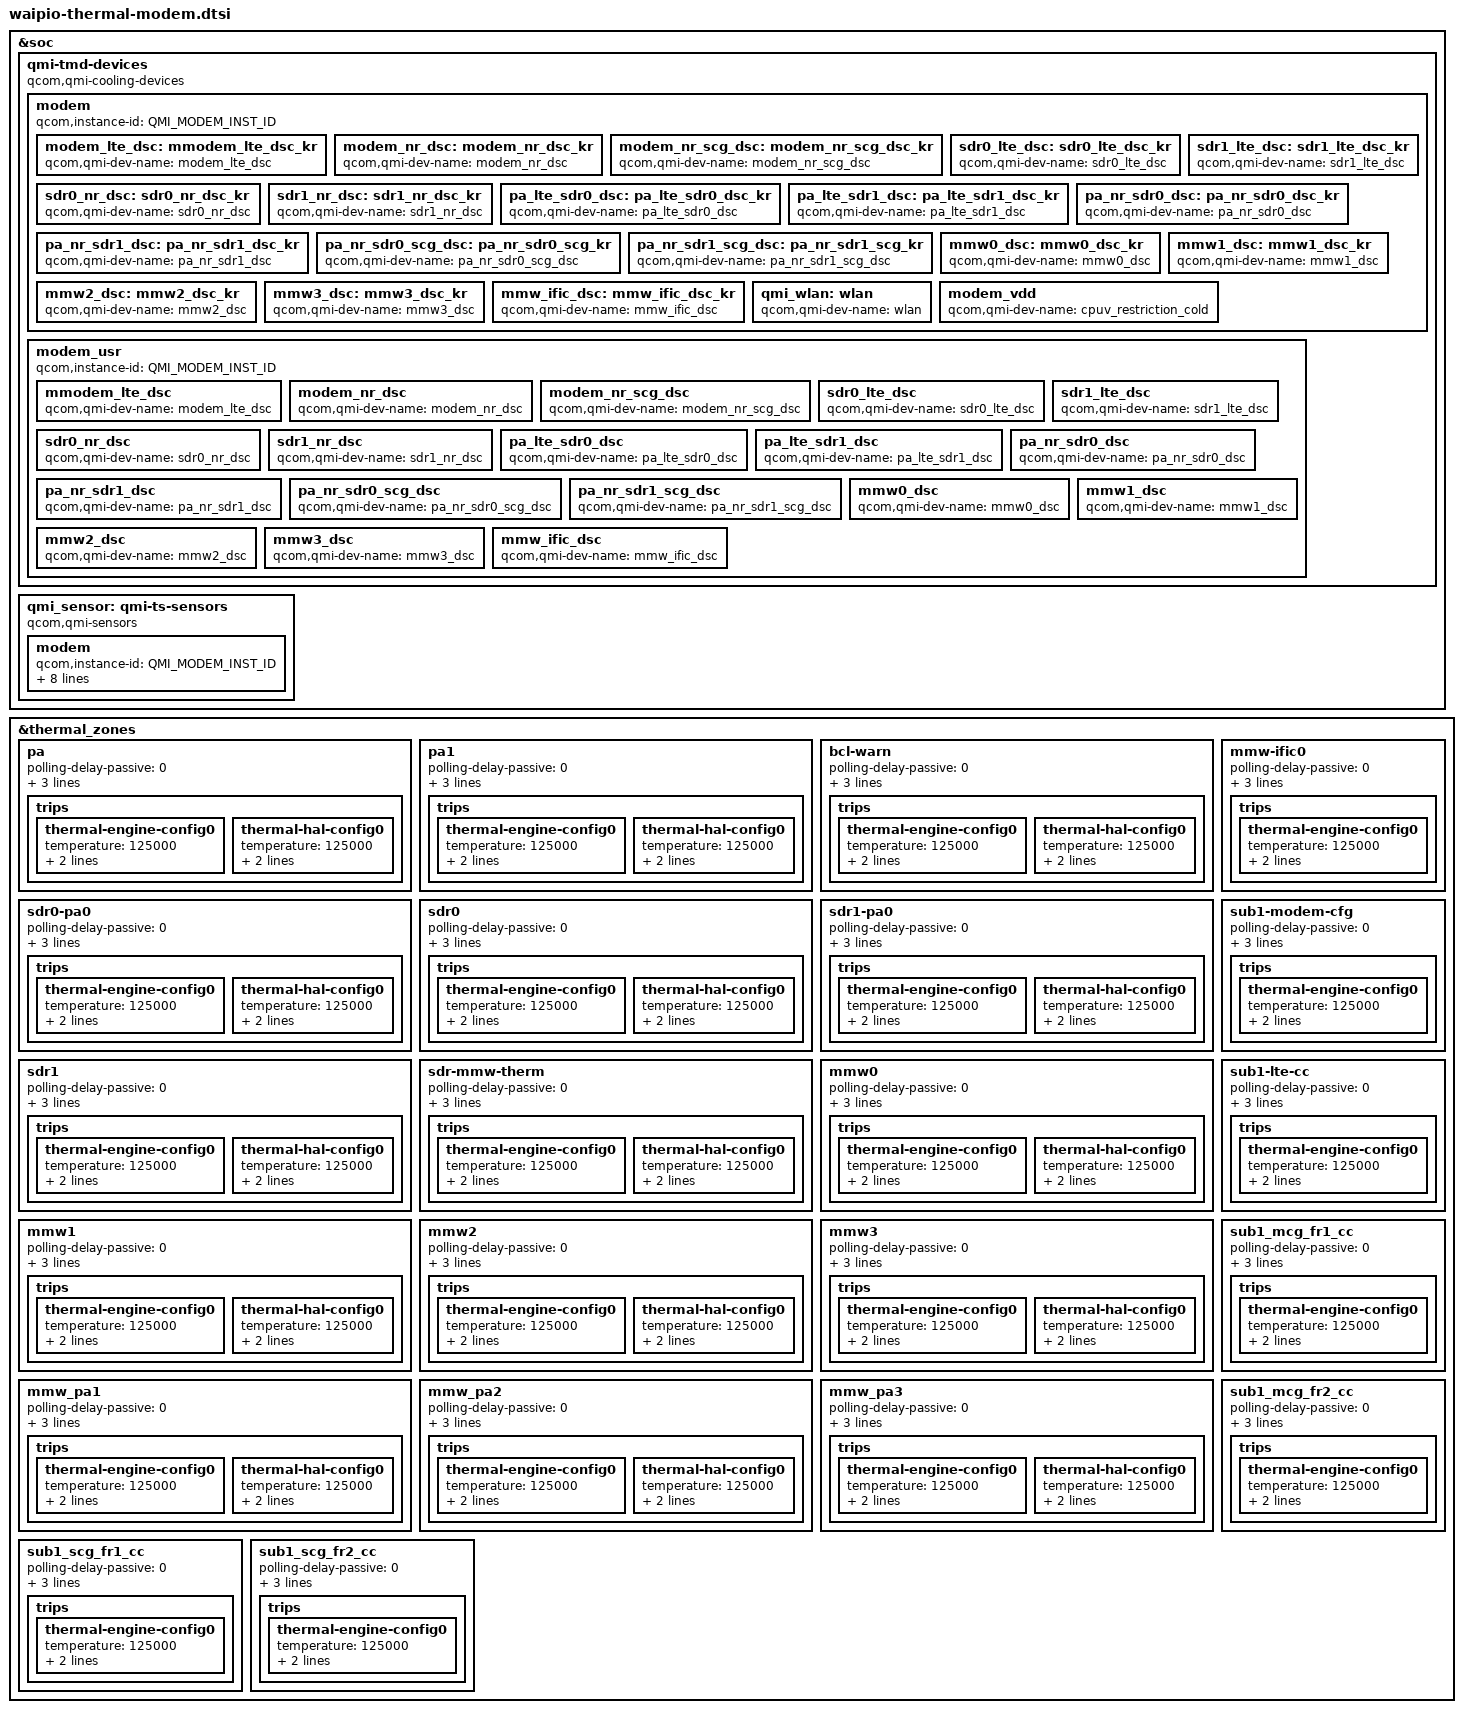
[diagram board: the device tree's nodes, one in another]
#include <dt-bindings/thermal/thermal_qti.h>

&soc {
	qmi-tmd-devices {
		compatible = "qcom,qmi-cooling-devices";

		modem {
			qcom,instance-id = <QMI_MODEM_INST_ID>;

			modem_lte_dsc: mmodem_lte_dsc_kr {
				qcom,qmi-dev-name = "modem_lte_dsc";
				#cooling-cells = <2>;
			};

			modem_nr_dsc: modem_nr_dsc_kr {
				qcom,qmi-dev-name = "modem_nr_dsc";
				#cooling-cells = <2>;
			};

			modem_nr_scg_dsc: modem_nr_scg_dsc_kr {
				qcom,qmi-dev-name = "modem_nr_scg_dsc";
				#cooling-cells = <2>;
			};

			sdr0_lte_dsc: sdr0_lte_dsc_kr {
				qcom,qmi-dev-name = "sdr0_lte_dsc";
				#cooling-cells = <2>;
			};

			sdr1_lte_dsc: sdr1_lte_dsc_kr {
				qcom,qmi-dev-name = "sdr1_lte_dsc";
				#cooling-cells = <2>;
			};

			sdr0_nr_dsc: sdr0_nr_dsc_kr {
				qcom,qmi-dev-name = "sdr0_nr_dsc";
				#cooling-cells = <2>;
			};

			sdr1_nr_dsc: sdr1_nr_dsc_kr {
				qcom,qmi-dev-name = "sdr1_nr_dsc";
				#cooling-cells = <2>;
			};

			pa_lte_sdr0_dsc: pa_lte_sdr0_dsc_kr {
				qcom,qmi-dev-name = "pa_lte_sdr0_dsc";
				#cooling-cells = <2>;
			};

			pa_lte_sdr1_dsc: pa_lte_sdr1_dsc_kr {
				qcom,qmi-dev-name = "pa_lte_sdr1_dsc";
				#cooling-cells = <2>;
			};

			pa_nr_sdr0_dsc: pa_nr_sdr0_dsc_kr {
				qcom,qmi-dev-name = "pa_nr_sdr0_dsc";
				#cooling-cells = <2>;
			};

			pa_nr_sdr1_dsc: pa_nr_sdr1_dsc_kr {
				qcom,qmi-dev-name = "pa_nr_sdr1_dsc";
				#cooling-cells = <2>;
			};

			pa_nr_sdr0_scg_dsc: pa_nr_sdr0_scg_kr {
				qcom,qmi-dev-name = "pa_nr_sdr0_scg_dsc";
				#cooling-cells = <2>;
			};

			pa_nr_sdr1_scg_dsc: pa_nr_sdr1_scg_kr {
				qcom,qmi-dev-name = "pa_nr_sdr1_scg_dsc";
				#cooling-cells = <2>;
			};

			mmw0_dsc: mmw0_dsc_kr {
				qcom,qmi-dev-name = "mmw0_dsc";
				#cooling-cells = <2>;
			};

			mmw1_dsc: mmw1_dsc_kr {
				qcom,qmi-dev-name = "mmw1_dsc";
				#cooling-cells = <2>;
			};

			mmw2_dsc: mmw2_dsc_kr {
				qcom,qmi-dev-name = "mmw2_dsc";
				#cooling-cells = <2>;
			};

			mmw3_dsc: mmw3_dsc_kr {
				qcom,qmi-dev-name = "mmw3_dsc";
				#cooling-cells = <2>;
			};

			mmw_ific_dsc: mmw_ific_dsc_kr {
				qcom,qmi-dev-name = "mmw_ific_dsc";
				#cooling-cells = <2>;
			};

			qmi_wlan: wlan {
				qcom,qmi-dev-name = "wlan";
				#cooling-cells = <2>;
			};

			modem_vdd: modem_vdd {
				qcom,qmi-dev-name = "cpuv_restriction_cold";
				#cooling-cells = <2>;
			};
		};

		modem_usr {
			qcom,instance-id = <QMI_MODEM_INST_ID>;

			mmodem_lte_dsc {
				qcom,qmi-dev-name = "modem_lte_dsc";
			};

			modem_nr_dsc {
				qcom,qmi-dev-name = "modem_nr_dsc";
			};

			modem_nr_scg_dsc {
				qcom,qmi-dev-name = "modem_nr_scg_dsc";
			};

			sdr0_lte_dsc {
				qcom,qmi-dev-name = "sdr0_lte_dsc";
			};

			sdr1_lte_dsc {
				qcom,qmi-dev-name = "sdr1_lte_dsc";
			};

			sdr0_nr_dsc {
				qcom,qmi-dev-name = "sdr0_nr_dsc";
			};

			sdr1_nr_dsc {
				qcom,qmi-dev-name = "sdr1_nr_dsc";
			};

			pa_lte_sdr0_dsc {
				qcom,qmi-dev-name = "pa_lte_sdr0_dsc";
			};

			pa_lte_sdr1_dsc {
				qcom,qmi-dev-name = "pa_lte_sdr1_dsc";
			};

			pa_nr_sdr0_dsc {
				qcom,qmi-dev-name = "pa_nr_sdr0_dsc";
			};

			pa_nr_sdr1_dsc {
				qcom,qmi-dev-name = "pa_nr_sdr1_dsc";
			};

			pa_nr_sdr0_scg_dsc {
				qcom,qmi-dev-name = "pa_nr_sdr0_scg_dsc";
			};

			pa_nr_sdr1_scg_dsc {
				qcom,qmi-dev-name = "pa_nr_sdr1_scg_dsc";
			};

			mmw0_dsc {
				qcom,qmi-dev-name = "mmw0_dsc";
			};

			mmw1_dsc {
				qcom,qmi-dev-name = "mmw1_dsc";
			};

			mmw2_dsc {
				qcom,qmi-dev-name = "mmw2_dsc";
			};

			mmw3_dsc {
				qcom,qmi-dev-name = "mmw3_dsc";
			};

			mmw_ific_dsc {
				qcom,qmi-dev-name = "mmw_ific_dsc";
			};
		};
	};

	qmi_sensor: qmi-ts-sensors {
		compatible = "qcom,qmi-sensors";
		#thermal-sensor-cells = <1>;

		modem {
			qcom,instance-id = <QMI_MODEM_INST_ID>;
			qcom,qmi-sensor-names = "pa",
						"pa_1",
						"sys_therm1",
						"sys_therm2",
						"modem_bcl_warn",
						"modem_tsens",
						"modem_tsens1",
						"sdr0_pa0",
						"sdr0",
						"sdr1_pa0",
						"sdr1",
						"sdr_mmw_therm",
						"mmw0",
						"mmw1",
						"mmw2",
						"mmw3",
						"mmw_pa1",
						"mmw_pa2",
						"mmw_pa3",
						"mmw_ific0",
						"sub1_modem_cfg",
						"sub1_lte_cc",
						"sub1_mcg_fr1_cc",
						"sub1_mcg_fr2_cc",
						"sub1_scg_fr1_cc",
						"sub1_scg_fr2_cc";
		};
	};
};

&thermal_zones {
	pa {
		polling-delay-passive = <0>;
		polling-delay = <0>;
		thermal-sensors = <&qmi_sensor
				(QMI_MODEM_INST_ID+QMI_PA)>;
		trips {
			thermal-engine-config0 {
				temperature = <125000>;
				hysteresis = <1000>;
				type = "passive";
			};

			thermal-hal-config0 {
				temperature = <125000>;
				hysteresis = <1000>;
				type = "passive";
			};
		};
	};

	pa1 {
		polling-delay-passive = <0>;
		polling-delay = <0>;
		thermal-sensors = <&qmi_sensor
				(QMI_MODEM_INST_ID+QMI_PA_1)>;
		trips {
			thermal-engine-config0 {
				temperature = <125000>;
				hysteresis = <1000>;
				type = "passive";
			};

			thermal-hal-config0 {
				temperature = <125000>;
				hysteresis = <1000>;
				type = "passive";
			};
		};
	};

	bcl-warn {
		polling-delay-passive = <0>;
		polling-delay = <0>;
		thermal-sensors = <&qmi_sensor
				(QMI_MODEM_INST_ID+QMI_BCL_WARN)>;
		trips {
			thermal-engine-config0 {
				temperature = <125000>;
				hysteresis = <1000>;
				type = "passive";
			};

			thermal-hal-config0 {
				temperature = <125000>;
				hysteresis = <1000>;
				type = "passive";
			};
		};
	};

	sdr0-pa0 {
		polling-delay-passive = <0>;
		polling-delay = <0>;
		thermal-sensors = <&qmi_sensor
				(QMI_MODEM_INST_ID+QMI_SDR0_PA0)>;
		trips {
			thermal-engine-config0 {
				temperature = <125000>;
				hysteresis = <1000>;
				type = "passive";
			};

			thermal-hal-config0 {
				temperature = <125000>;
				hysteresis = <1000>;
				type = "passive";
			};
		};
	};

	sdr0 {
		polling-delay-passive = <0>;
		polling-delay = <0>;
		thermal-sensors = <&qmi_sensor
				(QMI_MODEM_INST_ID+QMI_SDR0)>;
		trips {
			thermal-engine-config0 {
				temperature = <125000>;
				hysteresis = <1000>;
				type = "passive";
			};

			thermal-hal-config0 {
				temperature = <125000>;
				hysteresis = <1000>;
				type = "passive";
			};
		};
	};

	sdr1-pa0 {
		polling-delay-passive = <0>;
		polling-delay = <0>;
		thermal-sensors = <&qmi_sensor
				(QMI_MODEM_INST_ID+QMI_SDR1_PA0)>;
		trips {
			thermal-engine-config0 {
				temperature = <125000>;
				hysteresis = <1000>;
				type = "passive";
			};

			thermal-hal-config0 {
				temperature = <125000>;
				hysteresis = <1000>;
				type = "passive";
			};
		};
	};

	sdr1 {
		polling-delay-passive = <0>;
		polling-delay = <0>;
		thermal-sensors = <&qmi_sensor
				(QMI_MODEM_INST_ID+QMI_SDR1)>;
		trips {
			thermal-engine-config0 {
				temperature = <125000>;
				hysteresis = <1000>;
				type = "passive";
			};

			thermal-hal-config0 {
				temperature = <125000>;
				hysteresis = <1000>;
				type = "passive";
			};
		};
	};

	sdr-mmw-therm {
		polling-delay-passive = <0>;
		polling-delay = <0>;
		thermal-sensors = <&qmi_sensor
				(QMI_MODEM_INST_ID+QMI_SDR_MMW)>;
		trips {
			thermal-engine-config0 {
				temperature = <125000>;
				hysteresis = <1000>;
				type = "passive";
			};

			thermal-hal-config0 {
				temperature = <125000>;
				hysteresis = <1000>;
				type = "passive";
			};
		};
	};

	mmw0 {
		polling-delay-passive = <0>;
		polling-delay = <0>;
		thermal-sensors = <&qmi_sensor
				(QMI_MODEM_INST_ID+QMI_MMW0)>;
		trips {
			thermal-engine-config0 {
				temperature = <125000>;
				hysteresis = <1000>;
				type = "passive";
			};

			thermal-hal-config0 {
				temperature = <125000>;
				hysteresis = <1000>;
				type = "passive";
			};
		};
	};

	mmw1 {
		polling-delay-passive = <0>;
		polling-delay = <0>;
		thermal-sensors = <&qmi_sensor
				(QMI_MODEM_INST_ID+QMI_MMW1)>;
		trips {
			thermal-engine-config0 {
				temperature = <125000>;
				hysteresis = <1000>;
				type = "passive";
			};

			thermal-hal-config0 {
				temperature = <125000>;
				hysteresis = <1000>;
				type = "passive";
			};
		};
	};

	mmw2 {
		polling-delay-passive = <0>;
		polling-delay = <0>;
		thermal-sensors = <&qmi_sensor
				(QMI_MODEM_INST_ID+QMI_MMW2)>;
		trips {
			thermal-engine-config0 {
				temperature = <125000>;
				hysteresis = <1000>;
				type = "passive";
			};

			thermal-hal-config0 {
				temperature = <125000>;
				hysteresis = <1000>;
				type = "passive";
			};
		};
	};

	mmw3 {
		polling-delay-passive = <0>;
		polling-delay = <0>;
		thermal-sensors = <&qmi_sensor
				(QMI_MODEM_INST_ID+QMI_MMW3)>;
		trips {
			thermal-engine-config0 {
				temperature = <125000>;
				hysteresis = <1000>;
				type = "passive";
			};

			thermal-hal-config0 {
				temperature = <125000>;
				hysteresis = <1000>;
				type = "passive";
			};
		};
	};

	mmw_pa1 {
		polling-delay-passive = <0>;
		polling-delay = <0>;
		thermal-sensors = <&qmi_sensor
				(QMI_MODEM_INST_ID+QMI_MMW_PA1)>;
		trips {
			thermal-engine-config0 {
				temperature = <125000>;
				hysteresis = <1000>;
				type = "passive";
			};

			thermal-hal-config0 {
				temperature = <125000>;
				hysteresis = <1000>;
				type = "passive";
			};
		};
	};

	mmw_pa2 {
		polling-delay-passive = <0>;
		polling-delay = <0>;
		thermal-sensors = <&qmi_sensor
				(QMI_MODEM_INST_ID+QMI_MMW_PA2)>;
		trips {
			thermal-engine-config0 {
				temperature = <125000>;
				hysteresis = <1000>;
				type = "passive";
			};

			thermal-hal-config0 {
				temperature = <125000>;
				hysteresis = <1000>;
				type = "passive";
			};
		};
	};

	mmw_pa3 {
		polling-delay-passive = <0>;
		polling-delay = <0>;
		thermal-sensors = <&qmi_sensor
				(QMI_MODEM_INST_ID+QMI_MMW_PA3)>;
		trips {
			thermal-engine-config0 {
				temperature = <125000>;
				hysteresis = <1000>;
				type = "passive";
			};

			thermal-hal-config0 {
				temperature = <125000>;
				hysteresis = <1000>;
				type = "passive";
			};
		};
	};

	mmw-ific0 {
		polling-delay-passive = <0>;
		polling-delay = <0>;
		thermal-sensors = <&qmi_sensor
				(QMI_MODEM_INST_ID+QMI_MMW_IFIC0)>;
		trips {
			thermal-engine-config0 {
				temperature = <125000>;
				hysteresis = <1000>;
				type = "passive";
			};
		};
	};

	sub1-modem-cfg {
		polling-delay-passive = <0>;
		polling-delay = <0>;
		thermal-sensors = <&qmi_sensor
				(QMI_MODEM_INST_ID+QMI_SUB1_MODEM_CFG)>;
		trips {
			thermal-engine-config0 {
				temperature = <125000>;
				hysteresis = <1000>;
				type = "passive";
			};
		};
	};

	sub1-lte-cc {
		polling-delay-passive = <0>;
		polling-delay = <0>;
		thermal-sensors = <&qmi_sensor
				(QMI_MODEM_INST_ID+QMI_SUB1_LTE_CC)>;
		trips {
			thermal-engine-config0 {
				temperature = <125000>;
				hysteresis = <1000>;
				type = "passive";
			};
		};
	};

	sub1_mcg_fr1_cc {
		polling-delay-passive = <0>;
		polling-delay = <0>;
		thermal-sensors = <&qmi_sensor
				(QMI_MODEM_INST_ID+QMI_SUB1_MCG_FR1_CC)>;
		trips {
			thermal-engine-config0 {
				temperature = <125000>;
				hysteresis = <1000>;
				type = "passive";
			};
		};
	};

	sub1_mcg_fr2_cc {
		polling-delay-passive = <0>;
		polling-delay = <0>;
		thermal-sensors = <&qmi_sensor
				(QMI_MODEM_INST_ID+QMI_SUB1_MCG_FR2_CC)>;
		trips {
			thermal-engine-config0 {
				temperature = <125000>;
				hysteresis = <1000>;
				type = "passive";
			};
		};
	};

	sub1_scg_fr1_cc {
		polling-delay-passive = <0>;
		polling-delay = <0>;
		thermal-sensors = <&qmi_sensor
				(QMI_MODEM_INST_ID+QMI_SUB1_SCG_FR1_CC)>;
		trips {
			thermal-engine-config0 {
				temperature = <125000>;
				hysteresis = <1000>;
				type = "passive";
			};
		};
	};

	sub1_scg_fr2_cc {
		polling-delay-passive = <0>;
		polling-delay = <0>;
		thermal-sensors = <&qmi_sensor
				(QMI_MODEM_INST_ID+QMI_SUB1_SCG_FR2_CC)>;
		trips {
			thermal-engine-config0 {
				temperature = <125000>;
				hysteresis = <1000>;
				type = "passive";
			};
		};
	};
};
